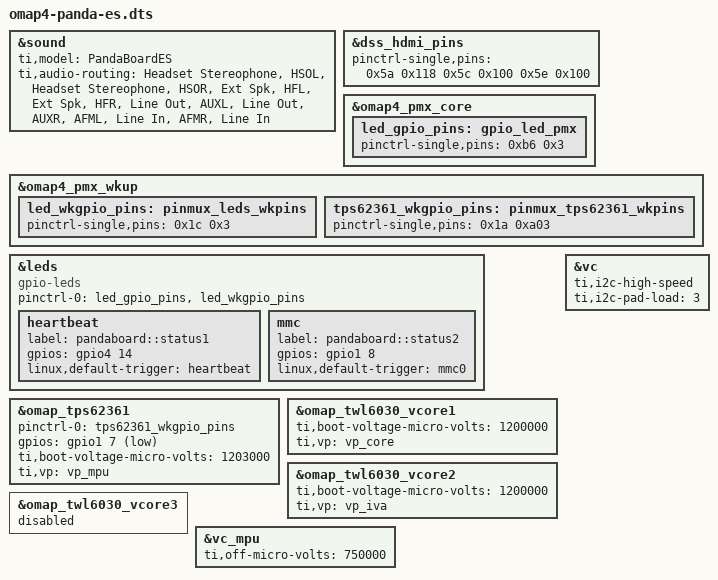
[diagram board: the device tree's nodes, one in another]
/*
 * Copyright (C) 2012 Texas Instruments Incorporated - http://www.ti.com/
 *
 * This program is free software; you can redistribute it and/or modify
 * it under the terms of the GNU General Public License version 2 as
 * published by the Free Software Foundation.
 */
/dts-v1/;

/include/ "omap4460.dtsi"
/include/ "omap4-panda-common.dtsi"

/* Audio routing is differnet between PandaBoard4430 and PandaBoardES */
&sound {
	ti,model = "PandaBoardES";

	/* Audio routing */
	ti,audio-routing =
		"Headset Stereophone", "HSOL",
		"Headset Stereophone", "HSOR",
		"Ext Spk", "HFL",
		"Ext Spk", "HFR",
		"Line Out", "AUXL",
		"Line Out", "AUXR",
		"AFML", "Line In",
		"AFMR", "Line In";
};

/* PandaboardES has external pullups on SCL & SDA */
&dss_hdmi_pins {
	pinctrl-single,pins = <
		0x5a 0x118	/* hdmi_cec.hdmi_cec INPUT PULLUP | MODE 0 */
		0x5c 0x100	/* hdmi_scl.hdmi_scl INPUT | MODE 0 */
		0x5e 0x100	/* hdmi_sda.hdmi_sda INPUT | MODE 0 */
		>;
};

&omap4_pmx_core {
	led_gpio_pins: gpio_led_pmx {
		pinctrl-single,pins = <
			0xb6 0x3	/* gpio_110 OUTPUT | MODE 3 */
		>;
	};
};

&omap4_pmx_wkup {
	led_wkgpio_pins: pinmux_leds_wkpins {
		pinctrl-single,pins = <
			0x1c 0x3	/* gpio_wk8 OUTPUT | MODE 3 */
		>;
	};

	tps62361_wkgpio_pins: pinmux_tps62361_wkpins {
		pinctrl-single,pins = <
			0x1a 0xa03	/* gpio_wk7 OUTPUT | MODE 3 |OFF_HI */
		>;
	};
};

&leds {
	compatible = "gpio-leds";
	pinctrl-names = "default";
	pinctrl-0 = <
		&led_gpio_pins
		&led_wkgpio_pins
	>;

	heartbeat {
		label = "pandaboard::status1";
		gpios = <&gpio4 14 0>;
		linux,default-trigger = "heartbeat";
	};
	mmc {
		label = "pandaboard::status2";
		gpios = <&gpio1 8 0>;
		linux,default-trigger = "mmc0";
	};
};

#define TPS62361_PD_VSEL0
#include "tps62361.dtsi"

/* Board Specific configuration */
&omap_tps62361 {
	pinctrl-names = "default";
	pinctrl-0 = <
		&tps62361_wkgpio_pins
	>;
	gpios = <&gpio1 7 1>;	/* gpio_wk7 Set to HIGH */

	ti,boot-voltage-micro-volts=<1203000>;
	ti,vp=<&vp_mpu>;
};

&omap_twl6030_vcore1 {
	ti,boot-voltage-micro-volts=<1200000>;
	ti,vp=<&vp_core>;
};

&omap_twl6030_vcore2 {
	ti,boot-voltage-micro-volts=<1200000>;
	ti,vp = <&vp_iva>;
};

&omap_twl6030_vcore3 {
	status = "disabled";
};

&vc_mpu {
	/* Due to potential lifetime impact, OFF voltage is set to RET V: TPS*/
	ti,off-micro-volts = <750000>;
};

&vc {
	ti,i2c-high-speed;
	ti,i2c-pad-load=<3>;
};
